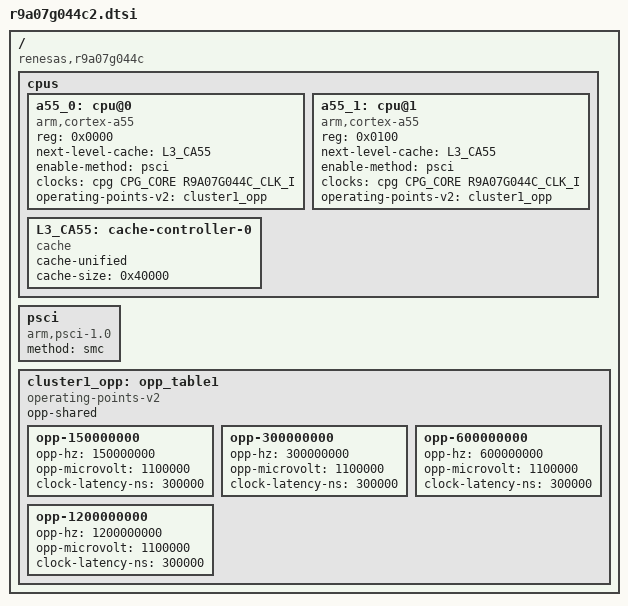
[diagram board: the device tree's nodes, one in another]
// SPDX-License-Identifier: GPL-2.0
/*
 * Device Tree Source for the RZ/G2LC Dual A55 (R9A07G044C2) SoC
 *
 * Copyright (C) 2021 Renesas Electronics Corp.
 */

#include "r9a07g044c.dtsi"

/ {
	compatible = "renesas,r9a07g044c", "renesas,r9a07g044c2";
	#address-cells = <2>;
	#size-cells = <2>;

	cpus {
		#address-cells = <1>;
		#size-cells = <0>;

		a55_0: cpu@0 {
			compatible = "arm,cortex-a55";
			reg = <0x0000>;
			device_type = "cpu";
			next-level-cache = <&L3_CA55>;
			enable-method = "psci";
			clocks = <&cpg CPG_CORE R9A07G044C_CLK_I>;
			operating-points-v2 = <&cluster1_opp>;
		};

		a55_1: cpu@1 {
			compatible = "arm,cortex-a55";
			reg = <0x0100>;
			device_type = "cpu";
			next-level-cache = <&L3_CA55>;
			enable-method = "psci";
			clocks = <&cpg CPG_CORE R9A07G044C_CLK_I>;
			operating-points-v2 = <&cluster1_opp>;
		};

		L3_CA55: cache-controller-0 {
			compatible = "cache";
			cache-unified;
			cache-size = <0x40000>;
		};
	};

	psci {
		compatible = "arm,psci-1.0", "arm,psci-0.2";
		method = "smc";
	};

	cluster1_opp: opp_table1 {
		compatible = "operating-points-v2";
		opp-shared;

		opp-150000000 {
			opp-hz = /bits/ 64 <150000000>;
			opp-microvolt = <1100000>;
			clock-latency-ns = <300000>;
		};

		opp-300000000 {
			opp-hz = /bits/ 64 <300000000>;
			opp-microvolt = <1100000>;
			clock-latency-ns = <300000>;
		};

		opp-600000000 {
			opp-hz = /bits/ 64 <600000000>;
			opp-microvolt = <1100000>;
			clock-latency-ns = <300000>;
		};

		opp-1200000000 {
			opp-hz = /bits/ 64 <1200000000>;
			opp-microvolt = <1100000>;
			clock-latency-ns = <300000>;
		};
	};
};

